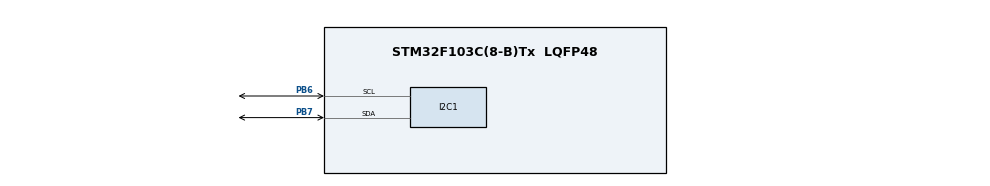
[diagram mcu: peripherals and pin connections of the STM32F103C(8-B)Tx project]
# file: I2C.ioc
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Mcu.Family=STM32F1
Mcu.Name=STM32F103C(8-B)Tx
Mcu.Package=LQFP48
NVIC.PriorityGroup=NVIC_PRIORITYGROUP_4
PA13.Mode=Serial_Wire
PA13.Signal=SYS_JTMS-SWDIO
PA14.Mode=Serial_Wire
PA14.Signal=SYS_JTCK-SWCLK
PB6.Mode=I2C
PB6.Signal=I2C1_SCL
PB7.Mode=I2C
PB7.Signal=I2C1_SDA
ProjectManager.HeapSize=0x200
ProjectManager.StackSize=0x400
ProjectManager.TargetToolchain=MDK-ARM V5.32
RCC.APB1Freq_Value=8000000
RCC.APB2Freq_Value=8000000
board=custom

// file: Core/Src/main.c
/* USER CODE BEGIN Header */
/**
  ******************************************************************************
  * @file           : main.c
  * @brief          : Main program body
  ******************************************************************************
  * @attention
  *
  * Copyright (c) 2025 STMicroelectronics.
  * All rights reserved.
  *
  * This software is licensed under terms that can be found in the LICENSE file
  * in the root directory of this software component.
  * If no LICENSE file comes with this software, it is provided AS-IS.
  *
  ******************************************************************************
  */
/* USER CODE END Header */
#include "main.h"

/* USER CODE BEGIN PD */
#define MPU_ADD			0x68 << 1

#define SMPRT_DIV_REG 0x19
#define GYRO_CONFIG_REG 0x1B
#define ACCEL_CONFIG_REG 0x1C
#define ACCEL_XOUT_H_REG 0x3B
#define TEMP_OUT_H_REG 0x41
#define GYRO_XOUT_H_REG 0x43
#define PWR_MGMT_1_REG 0x6B
#define WHO_AM_I_REG 0x75
/* USER CODE END PD */

I2C_HandleTypeDef hi2c1;

/* USER CODE BEGIN PV */
int16_t Accel_X_RAW = 0;
int16_t Accel_Y_RAW = 0;
int16_t Accel_Z_RAW = 0;

int16_t Gyro_X_RAW = 0;
int16_t Gyro_Y_RAW = 0;
int16_t Gyro_Z_RAW = 0;

float Ax, Ay, Az, Gx, Gy, Gz;
/* USER CODE END PV */

void SystemClock_Config(void);
static void MX_GPIO_Init(void);
static void MX_I2C1_Init(void);
/* USER CODE BEGIN PFP */
void MPU_Init(void);
void MPU_Read_Gyro(void);
void MPU_Read_Accel(void);

/* USER CODE END PFP */

/* USER CODE BEGIN 0 */
void MPU_Init(void) {
	uint8_t check;
	uint8_t data;

	HAL_I2C_Mem_Read(&hi2c1, MPU_ADD, 0x75, 1, &check, 1, 1000);
	if(check == 0x68) {
		data = 0x00;
		HAL_I2C_Mem_Write(&hi2c1, MPU_ADD, PWR_MGMT_1_REG, 1, &data, 1, 1000);
		data = 0x07;
		HAL_I2C_Mem_Write(&hi2c1, MPU_ADD, SMPRT_DIV_REG, 1, &data, 1, 1000);
		data = 0x00;
		HAL_I2C_Mem_Write(&hi2c1, MPU_ADD, GYRO_CONFIG_REG, 1, &data,1 , 1000);
		data = 0x00;
		HAL_I2C_Mem_Write(&hi2c1, MPU_ADD, ACCEL_CONFIG_REG, 1, &data,1 , 1000);
	}
}

void MPU_Read_Gyro(void) {
	uint8_t Rec_Data[6];

	HAL_I2C_Mem_Read(&hi2c1, MPU_ADD, GYRO_XOUT_H_REG, 1, Rec_Data, 6, 1000);
	Gyro_X_RAW = (uint16_t) (Rec_Data[0] << 8 | Rec_Data[1]);
	Gyro_Y_RAW = (uint16_t) (Rec_Data[2] << 8 | Rec_Data[3]);
	Gyro_Z_RAW = (uint16_t) (Rec_Data[4] << 8 | Rec_Data[5]);

	Gx = (float) Gyro_X_RAW / 131.0;
	Gy = (float) Gyro_Y_RAW / 131.0;
	Gz = (float) Gyro_Z_RAW / 131.0;
}

void MPU_Read_Accel(void) {
	uint8_t Rec_Data[6];

	HAL_I2C_Mem_Read(&hi2c1, MPU_ADD, ACCEL_XOUT_H_REG, 1, Rec_Data, 6, 1000);
	Accel_X_RAW = (uint16_t) (Rec_Data[0] << 8 | Rec_Data[1]);
	Accel_Y_RAW = (uint16_t) (Rec_Data[2] << 8 | Rec_Data[3]);
	Accel_Z_RAW = (uint16_t) (Rec_Data[4] << 8 | Rec_Data[5]);

	Ax = (float) Accel_X_RAW / 16384.0;
	Ay = (float) Accel_Y_RAW / 16384.0;
	Az = (float) Accel_Z_RAW / 16384.0;
}

/* USER CODE END 0 */

int main(void)
{

  /* MCU Configuration--------------------------------------------------------*/

  /* Reset of all peripherals, Initializes the Flash interface and the Systick. */
  HAL_Init();

  /* Configure the system clock */
  SystemClock_Config();

  /* Initialize all configured peripherals */
  MX_GPIO_Init();
  MX_I2C1_Init();
  /* USER CODE BEGIN 2 */
	MPU_Init();
  /* USER CODE END 2 */

  /* Infinite loop */
  while (1)
  {

    /* USER CODE BEGIN 3 */
		MPU_Read_Accel();
		MPU_Read_Gyro();
		HAL_Delay(100);
  }
  /* USER CODE END 3 */
}

void SystemClock_Config(void)
{
  RCC_OscInitTypeDef RCC_OscInitStruct = {0};
  RCC_ClkInitTypeDef RCC_ClkInitStruct = {0};

  /** Initializes the RCC Oscillators according to the specified parameters
  * in the RCC_OscInitTypeDef structure.
  */
  RCC_OscInitStruct.OscillatorType = RCC_OSCILLATORTYPE_HSI;
  RCC_OscInitStruct.HSIState = RCC_HSI_ON;
  RCC_OscInitStruct.HSICalibrationValue = RCC_HSICALIBRATION_DEFAULT;
  RCC_OscInitStruct.PLL.PLLState = RCC_PLL_NONE;
  if (HAL_RCC_OscConfig(&RCC_OscInitStruct) != HAL_OK)
  {
    Error_Handler();
  }

  /** Initializes the CPU, AHB and APB buses clocks
  */
  RCC_ClkInitStruct.ClockType = RCC_CLOCKTYPE_HCLK|RCC_CLOCKTYPE_SYSCLK
                              |RCC_CLOCKTYPE_PCLK1|RCC_CLOCKTYPE_PCLK2;
  RCC_ClkInitStruct.SYSCLKSource = RCC_SYSCLKSOURCE_HSI;
  RCC_ClkInitStruct.AHBCLKDivider = RCC_SYSCLK_DIV1;
  RCC_ClkInitStruct.APB1CLKDivider = RCC_HCLK_DIV1;
  RCC_ClkInitStruct.APB2CLKDivider = RCC_HCLK_DIV1;

  if (HAL_RCC_ClockConfig(&RCC_ClkInitStruct, FLASH_LATENCY_0) != HAL_OK)
  {
    Error_Handler();
  }
}

static void MX_I2C1_Init(void)
{

  hi2c1.Instance = I2C1;
  hi2c1.Init.ClockSpeed = 100000;
  hi2c1.Init.DutyCycle = I2C_DUTYCYCLE_2;
  hi2c1.Init.OwnAddress1 = 0;
  hi2c1.Init.AddressingMode = I2C_ADDRESSINGMODE_7BIT;
  hi2c1.Init.DualAddressMode = I2C_DUALADDRESS_DISABLE;
  hi2c1.Init.OwnAddress2 = 0;
  hi2c1.Init.GeneralCallMode = I2C_GENERALCALL_DISABLE;
  hi2c1.Init.NoStretchMode = I2C_NOSTRETCH_DISABLE;
  if (HAL_I2C_Init(&hi2c1) != HAL_OK)
  {
    Error_Handler();
  }

}

static void MX_GPIO_Init(void)
{

  /* GPIO Ports Clock Enable */
  __HAL_RCC_GPIOA_CLK_ENABLE();
  __HAL_RCC_GPIOB_CLK_ENABLE();

}

void Error_Handler(void)
{
  __disable_irq();
  while (1)
  {
  }
}
